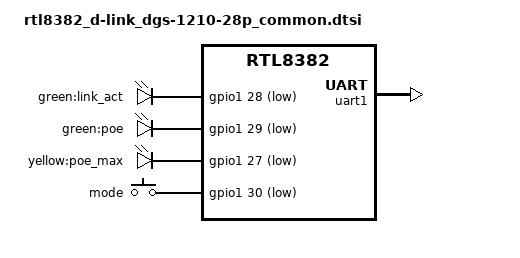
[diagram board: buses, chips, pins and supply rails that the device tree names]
// SPDX-License-Identifier: GPL-2.0-or-later OR MIT

&leds {
	link_act {
		label = "green:link_act";
		gpios = <&gpio1 28 GPIO_ACTIVE_LOW>;
	};

	poe {
		label = "green:poe";
		gpios = <&gpio1 29 GPIO_ACTIVE_LOW>;
	};

	poe_max {
		label = "yellow:poe_max";
		gpios = <&gpio1 27 GPIO_ACTIVE_LOW>;
	};
};

&keys {
	mode {
		label = "mode";
		gpios = <&gpio1 30 GPIO_ACTIVE_LOW>;
		linux,code = <BTN_0>;
	};
};

&uart1 {
	status = "okay";
};
